# prcm_aon_secure register map
Vendor: Texas Instruments
Peripheral module from a debugger description file (folder CC35X1E).
Registers are 32-bit, access per field, reset 0x0 unless marked. A register's access mark holds for its fields unless they carry their own. Offsets are as the file gives them; lines under a group give offsets from that group; [hi:lo] are bit positions; {n}, {i} and the like mark numbered series; 'fields as' and 'values as' point back to an identical list; <NAME> marks a mode.

## prcm_aon_secure (part 1 of 2)
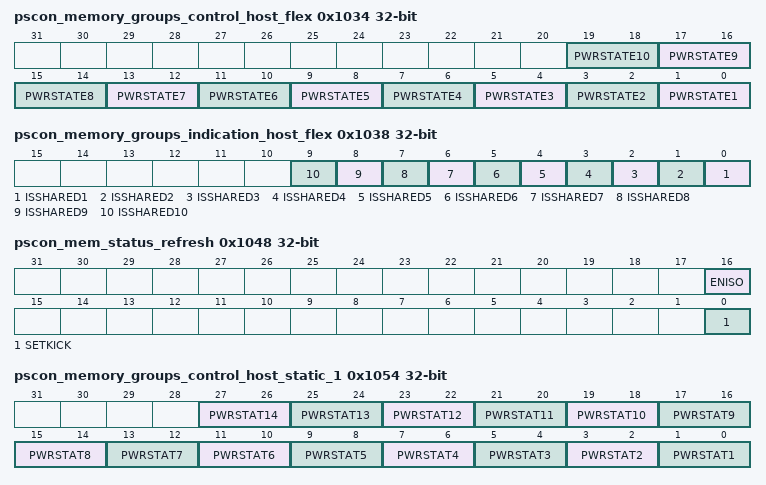
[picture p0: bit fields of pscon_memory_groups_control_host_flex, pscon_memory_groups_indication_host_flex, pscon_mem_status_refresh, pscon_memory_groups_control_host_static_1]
0x1034 pscon_memory_groups_control_host_flex reset not defined — PSCON Memory Groups Control Host Flex. Applicable only if MODE selected flex as HOST memory. Bank power State When owner IP Active/Sleep (power domain is ON/OFF) 0 - OFF/OFF 1 - Reserved 2 - ON/OFF 3 - ON/RET
  [2n-1:2n-2] PWRSTATE{n} rw (n=1..10) — POWER STATE {n} Group {n}
0x1038 pscon_memory_groups_indication_host_flex — PSCON Memory Groups Indication Host Flex Applicable only if MODE selected flex as HOST memory. Memory bank from this group is shared 1 - Shared 0 - Not Shared
  [n-1] ISSHARED{n} rw (n=1..10) — IS SHARED {n} Group {n}
0x1048 pscon_mem_status_refresh reset not defined — PSCON Memory Status Refresh
  [16] ENISO rw — Enable ISO During Refresh '1' - set ISO during refresh '0' - don't set ISO
  [0] SETKICK wo — Memory Host Set Refresh write clear triggers the refresh cycle. first set all memories to desired status, then fire the "refresh" pulse
0x104C pscon_mem_status_refresh_done ro reset 0x3 — Memory Refresh Status
  [0] DONE — memories status refresh is done
0x1054 pscon_memory_groups_control_host_static_1 reset not defined — PSCON Memory Groups Control Host Static. Bank power State When owner IP Active/Sleep (power domain is ON/OFF) 0 - OFF/OFF 1 - Reserved 2 - ON/OFF 3 - ON/RET
  [27:26] PWRSTAT14 rw — POWER STATE 14 Group 36
  [25:24] PWRSTAT13 rw — POWER STATE 13 Group 35
  [23:22] PWRSTAT12 rw — POWER STATE 12 HIF Group 34 - being used as shared memory
  [2n-1:2n-2] PWRSTAT{n} rw (n=1..11) — POWER STATE {n} Group {n+22}
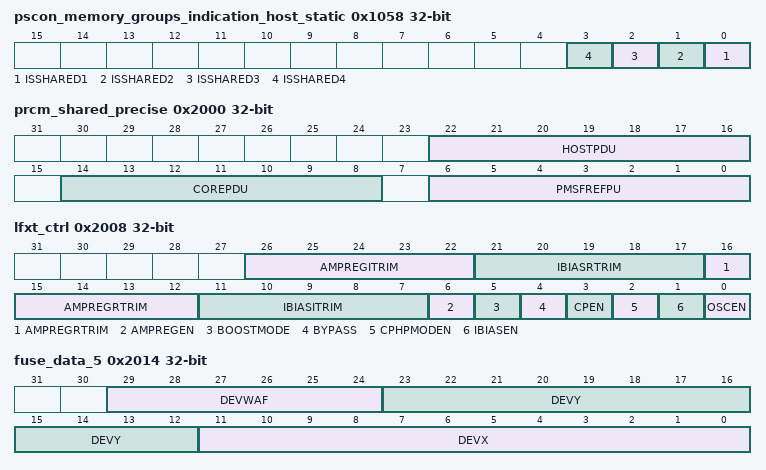
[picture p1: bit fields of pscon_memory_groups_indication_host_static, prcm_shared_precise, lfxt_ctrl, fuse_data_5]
0x1058 pscon_memory_groups_indication_host_static — Memory bank from this group is shared 1 - Shared 0 - Not Shared
  [n-1] ISSHARED{n} rw (n=1..4) — IS SHARED {n} Group {n+22}
0x105C prcm_logic_host_memory_status ro — Logic Host Memory Status
  [13:0] AONIN — Host Memory AONIN indication
0x1060 conectivity_stop reset 0x3 — Connectivity Stop
  [0] SET rw — '1' - Connectivity Stop '0' - Connectivity Start
0x1064 host_rst_ov_ctrl — HOST RESET OV CONTROL reset override control register, active low polarity: '0' - override reset (force reset line to 0, reset asserted, active low) '1' - don't override reset
  [0] PULSE wo — PULSE write clear
0x1068 sleepdeep — The register holds sleepdeep command for the host_mcu for debugging
  [0] SET rw — Set this field to force HOST deepsleep. It will cleared by HW when [HSLPIND] is '1'.
0x2000 prcm_shared_precise — SHARED PRECISE override values for PRCM SHARED Modules
  [22:16] HOSTPDU rw — HOST POWER DOMAIN UP SET precise duration for HOST Power Domain UP - factor 4 slow CLK resolution 0 - 1 Slow CLKs 1 - 5 Slow CLKs 2 - 9 Slow CLKs 3 - 13 Slow CLKs ... 127 - 509 Slow CLKs
  [14:8] COREPDU rw — CORE POWER DOMAIN UP SET precise duration for CORE Power Domain UP - factor 4 slow CLK resolution 0 - 1 Slow CLKs 1 - 5 Slow CLKs 2 - 9 Slow CLKs 3 - 13 Slow CLKs ... 127 - 509 Slow CLKs
  [6:0] PMSFREFPU rw — PMS FREF PLL UP SET precise duration for CORE PRCM Shared UP - factor 4 slow CLK resolution 0 - 1 Slow CLKs 1 - 5 Slow CLKs 2 - 9 Slow CLKs 3 - 13 Slow CLKs ... 127 - 509 Slow CLKs
0x2008 lfxt_ctrl — LFXT CONTROL
  [26:22] AMPREGITRIM rw — AMPLITUDE REGULATION CURRENT TRIM Amplitude regulation current trim
  [21:17] IBIASRTRIM rw — IBIAS RTRIM Constant gm bias resistor ladder trim
  [16:12] AMPREGRTRIM rw — AMPLITUDE REGULATION RESISTOR TRIM Amplitude regulation resistor ladder trim
  [11:7] IBIASITRIM rw — IBIAS ITRIM Constant gm bias current trim
  [6] AMPREGEN rw — AMPLITUDE REGULATION ENABLE Enable amplitude regulation
  [5] BOOSTMODE rw — BOOST MODE Start-up pulse for bias current generation
  [4] BYPASS rw — Bypass LFXT
  [3] CPEN rw — Comparator (slicer) enable
  [2] CPHPMODEN rw — COMP HP MODE EN Comparator high current mode
  [1] IBIASEN rw — Enable constant-gm bias
  [0] OSCEN rw — Oscillator core enable
0x200C lfxt_spare
  [15:0] CTL rw — CTL lfxt spare reg
0x2010 lfosc_en ro — LFOSC ENABLE
  [0] GOOD — CLK GOOD LFOSC clock good indication based on clock qualification logic
0x2014 fuse_data_5 ro
  [29:24] DEVWAF, [23:12] DEVY, [11:0] DEVX
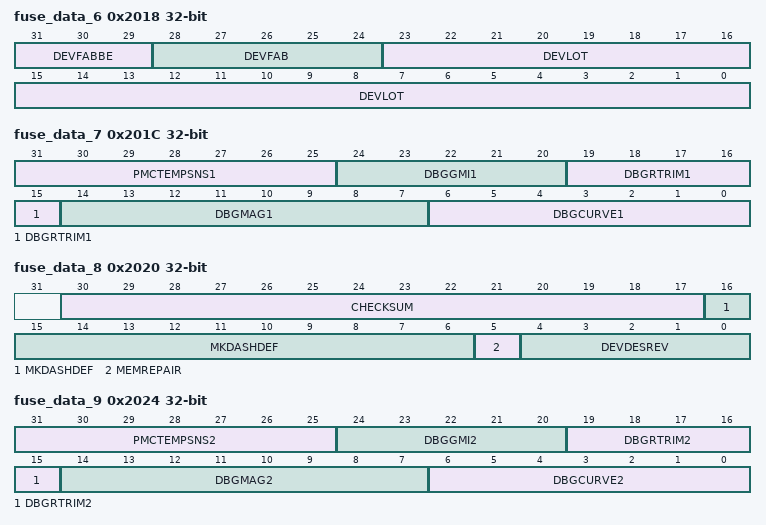
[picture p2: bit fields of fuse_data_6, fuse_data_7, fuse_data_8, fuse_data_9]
0x2018 fuse_data_6 ro
  [31:29] DEVFABBE, [28:24] DEVFAB, [23:0] DEVLOT
0x201C fuse_data_7 ro
  [31:25] PMCTEMPSNS1 — PMCIO TEMP SENSOR 1ST INSERTION For the first insertion.
  [24:20] DBGGMI1 — DIGBG GMI 1ST INSERTION For the first insertion. This field is used for trimming at boot after shift done.
  [19:15] DBGRTRIM1 — DIGBG RTRIM 1ST INSERTION For the first insertion. This field is used for trimming at boot after shift done.
  [14:7] DBGMAG1 — DIGBG MAG 1ST INSERTION For the first insertion. This field is used for trimming at boot after shift done.
  [6:0] DBGCURVE1 — DIGBG CURVE 1St INSERTION For the first insertion. This field is used for trimming at boot after shift done.
0x2020 fuse_data_8 ro
  [30:17] CHECKSUM — Checksum_TI_ DIEID_FUSE_DATA_5_6_8
  [16:6] MKDASHDEF — Make-defined
  [5] MEMREPAIR
  [4:0] DEVDESREV
0x2024 fuse_data_9 ro
  [31:25] PMCTEMPSNS2 — PMCIO TEMP SENSOR 2ND INSERTION For the second insertion. This field is used by SW only.
  [24:20] DBGGMI2 — DIGBG GMI 2ND INSERTION For the second insertion. This field is used by SW only.
  [19:15] DBGRTRIM2 — DIGBG RTRIM 2ND INSERTION For the second insertion. This field is used by SW only.
  [14:7] DBGMAG2 — DIGBG MAG 2ND INSERTION For the second insertion. This field is used by SW only.
  [6:0] DBGCURVE2 — DIGBG CURVE 2ND INSERTION For the second insertion. This field is used by SW only.
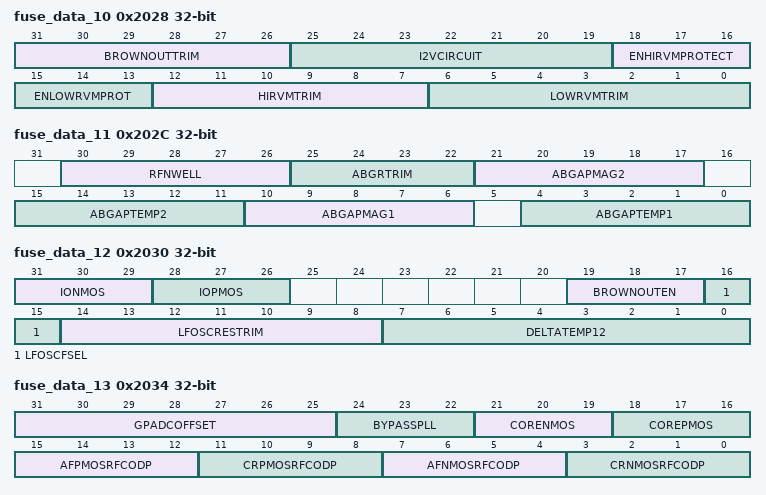
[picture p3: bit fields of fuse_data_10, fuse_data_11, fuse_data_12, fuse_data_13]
0x2028 fuse_data_10 ro
  [31:26] BROWNOUTTRIM — Brownout Trims
  [25:19] I2VCIRCUIT — I2V Circuit (Measure Current using GPADC)
  [18:16] ENHIRVMPROTECT — Enable High RVM protection (Specify whether to use the indication from RVM to reset the device). The RVM Enable can be override by SW (Boot RAM/Privilege mode). 0 - Disable (Ignore indication from RVM) Other (1-7) - Enable (Do not ignore indication from RVM) Consider Splitting the enables (including CRC)
  [15:13] ENLOWRVMPROT — Enable Low RVM protection (Specify whether to use the indication from RVM to reset the device). The RVM Enable can be override by SW (Boot RAM/Privilege mode). 0 - Disable (Ignore indication from RVM) Other (1-7) - Enable (Do not ignore indication from RVM)
  [12:7] HIRVMTRIM — High Digital Supply RVM Trimming
  [6:0] LOWRVMTRIM — Low Digital Supply RVM Trimming
0x202C fuse_data_11 ro
  [30:26] RFNWELL — RF NWELL Will be used to calculate during production the PMREF_V2I_RTRIM - Reference current to the RFCIO RX/TX modules (Can be part of OCP\, Not used in cold boot)
  [25:22] ABGRTRIM — ANA BG RTRIM This field is calculated bases on the 'RF_NWELL_Efuse' trimming results ANABG RTRIM (REFSYS_REG0<9:6>)
  [21:17] ABGAPMAG2 — ANA BGAP MAG 2ND INSERTION For the second insertion. This field is used by SW only.
  [15:11] ABGAPTEMP2 — ANABGAP TEMP 2ND INSERTION Trimming. For the second insertion. This field is used by SW only.
  [10:6] ABGAPMAG1 — ANA BGAP MAG 1St INSERTION For the first insertion. This field is used for trimming at boot after shift done.
  [4:0] ABGAPTEMP1 — ANABGAP TEMP 1ST INSERTION Trimming. For the first insertion. This field is used for trimming at boot after shift done.
0x2030 fuse_data_12 ro
  [31:29] IONMOS
  [28:26] IOPMOS
  [19:17] BROWNOUTEN — Brownout Enable/Disable: 0 - Disable Other (1-7) - Enable (When HW check these bits: if equal to '0' disable otherwise enable)
  [16:15] LFOSCFSEL — LFOSC Frequency Trimming
  [14:8] LFOSCRESTRIM — LFOSC Resistor Trimming
  [7:0] DELTATEMP12 — DELTA TEMP 1ST 2ND INSERTIONS Defines the delta temperature between the 1st and 2nd insertion in degC
0x2034 fuse_data_13 ro
  [31:25] GPADCOFFSET — GPADC OFFSET Capture the offset error of the GPADC
  [24:22] BYPASSPLL — Bypass SoC PLL Other (0-6) - Do not bypass SoC PLL 7 - Bypass SoC PLL
  [21:19] CORENMOS — CORE NMOS SOC ODP
  [18:16] COREPMOS — CORE PMOS SOC ODP
  [15:12] AFPMOSRFCODP — AF PMOS RFCIO ODP
  [11:8] CRPMOSRFCODP — CORE PMOS RFCIO ODP
  [7:4] AFNMOSRFCODP — AF NMOS RFCIO ODP
  [3:0] CRNMOSRFCODP — CORE NMOS RFCIO ODP
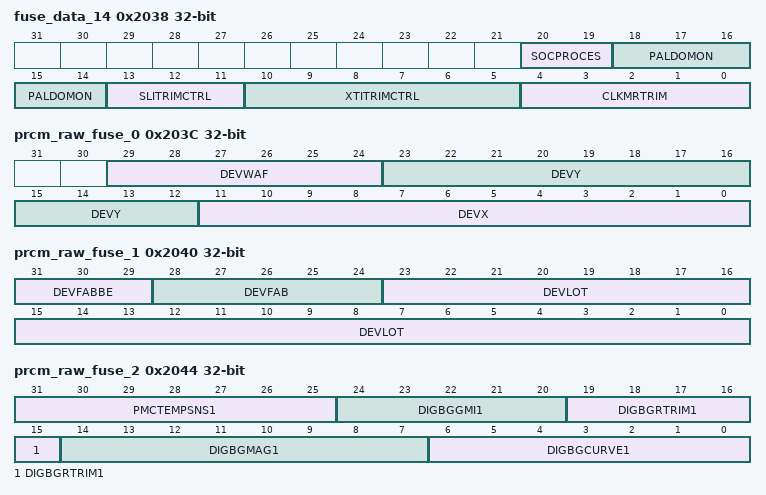
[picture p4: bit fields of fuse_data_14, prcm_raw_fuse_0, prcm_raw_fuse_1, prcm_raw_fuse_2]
0x2038 fuse_data_14 ro
  [20:19] SOCPROCES — SOC PROCESS The value is calculated based on Core PMOS/NMOS (SoC ODP) 2b'00 - Nominal 2b'01 - Weak 2b'10 - Strong
  [18:14] PALDOMON — PA LDO IN MONITOR PA LDO In ('Battery') Sensor Trimming for 3V
  [13:11] SLITRIMCTRL — Slicer ITRIM Control (CKM_SLICER_REG0<7:5>)
  [10:5] XTITRIMCTRL — XTAL ITRIM control (CKM_OSC_REG0<6:1>)
  [4:0] CLKMRTRIM — CLKM RTRIM This field is calculated base on the 'RF_NWELL_Efuse ' trimming results (CKM_SLICER_REG0<4:0>)
0x203C prcm_raw_fuse_0 ro — PRCM RAW FUSE 0 fuse line 5
  [29:24] DEVWAF, [23:12] DEVY, [11:0] DEVX
0x2040 prcm_raw_fuse_1 ro — PRCM RAW FUSE 1 fuse line 6
  [31:29] DEVFABBE, [28:24] DEVFAB, [23:0] DEVLOT
0x2044 prcm_raw_fuse_2 ro — PRCM RAW FUSE 2 fuse line 7
  [31:25] PMCTEMPSNS1 — PMCIO TEMP SENSOR 1ST INSERTION For the first insertion.
  [24:20] DIGBGGMI1 — DIGBG GMI 1ST INSERTION For the first insertion. This field is used for trimming at boot after shift done.
  [19:15] DIGBGRTRIM1 — DIGBG RTRIM 1ST INSERTION For the first insertion. This field is used for trimming at boot after shift done.
  [14:7] DIGBGMAG1 — DIGBG MAG 1ST INSERTION For the first insertion. This field is used for trimming at boot after shift done.
  [6:0] DIGBGCURVE1 — DIGBG CURVE 1ST INSERTION For the first insertion. This field is used for trimming at boot after shift done.
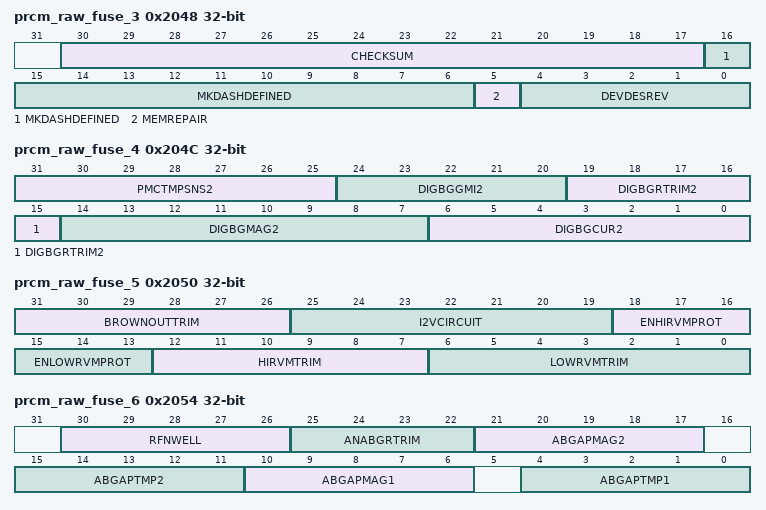
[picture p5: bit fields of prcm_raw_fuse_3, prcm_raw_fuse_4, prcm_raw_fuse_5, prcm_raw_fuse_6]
0x2048 prcm_raw_fuse_3 ro — PRCM RAW FUSE 3 fuse line 8
  [30:17] CHECKSUM — Checksum_TI_ DIEID_FUSE_DATA_5_6_8
  [16:6] MKDASHDEFINED — Make-defined
  [5] MEMREPAIR
  [4:0] DEVDESREV
0x204C prcm_raw_fuse_4 ro — PRCM RAW FUSE 4 fuse line 9
  [31:25] PMCTMPSNS2 — PMCIO TEMP SENSOR 2ND INSERTION For the second insertion. This field is used by SW only.
  [24:20] DIGBGGMI2 — DIGBG GMI 2ND INSERTION For the second insertion. This field is used by SW only.
  [19:15] DIGBGRTRIM2 — DIGBG RTRIM 2ND INSERTION For the second insertion. This field is used by SW only.
  [14:7] DIGBGMAG2 — DIGBG MAG 2ND INSERTION For the second insertion. This field is used by SW only.
  [6:0] DIGBGCUR2 — DIGBG CURVE 2ND INSERTION For the second insertion. This field is used by SW only.
0x2050 prcm_raw_fuse_5 ro — PRCM RAW FUSE 5 fuse line 10
  [31:26] BROWNOUTTRIM — Brownout Trims
  [25:19] I2VCIRCUIT — I2V Circuit (Measure Current using GPADC)
  [18:16] ENHIRVMPROT — Enable High RVM protection (Specify whether to use the indication from RVM to reset the device). The RVM Enable can be override by SW (Boot RAM/Privilege mode). 0 - Disable (Ignore indication from RVM) Other (1-7) - Enable (Do not ignore indication from RVM) Consider Splitting the enables (including CRC)
  [15:13] ENLOWRVMPROT — Enable Low RVM protection (Specify whether to use the indication from RVM to reset the device). The RVM Enable can be override by SW (Boot RAM/Privilege mode). 0 - Disable (Ignore indication from RVM) Other (1-7) - Enable (Do not ignore indication from RVM)
  [12:7] HIRVMTRIM — High Digital Supply RVM Trimming
  [6:0] LOWRVMTRIM — Low Digital Supply RVM Trimming
0x2054 prcm_raw_fuse_6 ro — PRCM RAW FUSE 6 fuse line 11
  [30:26] RFNWELL — RF NWELL EFUSE Will be used to calculate during production the PMREF_V2I_RTRIM - Reference current to the RFCIO RX/TX modules (Can be part of OCP\, Not used in cold boot)
  [25:22] ANABGRTRIM — ANA BG RTRIM This field is calculated bases on the 'RF_NWELL_Efuse' trimming results ANABG RTRIM (REFSYS_REG0<9:6>)
  [21:17] ABGAPMAG2 — ANA BGAP MAG 2ND INSERTION For the second insertion. This field is used by SW only.
  [15:11] ABGAPTMP2 — ANABGAP TEMP 2ND INSERTION Trimming. For the second insertion. This field is used by SW only.
  [10:6] ABGAPMAG1 — ANA BGAP MAG 1ST INSERTION For the first insertion. This field is used for trimming at boot after shift done.
  [4:0] ABGAPTMP1 — ANABGAP TEMP 1ST INSERTION Trimming. For the first insertion. This field is used for trimming at boot after shift done.
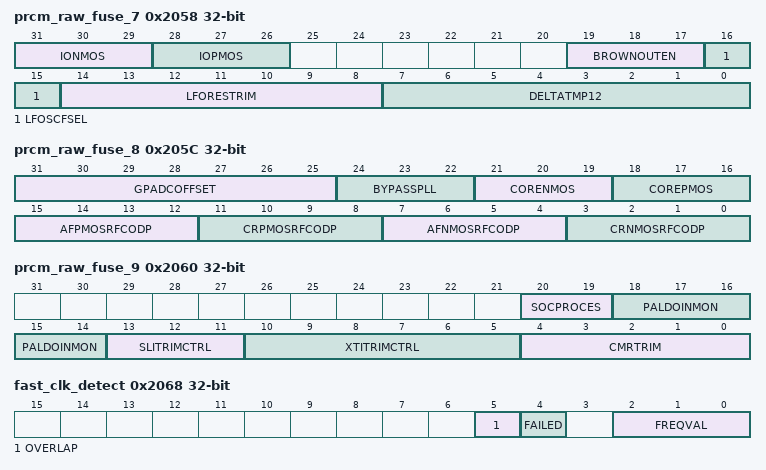
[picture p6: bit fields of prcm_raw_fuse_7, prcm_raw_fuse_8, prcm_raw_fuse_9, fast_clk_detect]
0x2058 prcm_raw_fuse_7 ro — PRCM RAW FUSE 7 fuse line 12
  [31:29] IONMOS
  [28:26] IOPMOS
  [19:17] BROWNOUTEN — Brownout Enable/Disable: 0 - Disable Other (1-7) - Enable (When HW check these bits: if equal to '0' disable otherwise enable)
  [16:15] LFOSCFSEL — LFOSC Frequency Trimming
  [14:8] LFORESTRIM — LFOSC Resistor Trimming
  [7:0] DELTATMP12 — DELTA TEMPERATURE 1ST 2ND INSERTIONS Defines the delta temperature between the 1st and 2nd insertion in degC
0x205C prcm_raw_fuse_8 ro — PRCM RAW FUSE 8 fuse line 13
  fields as fuse_data_13
0x2060 prcm_raw_fuse_9 ro — PRCM RAW FUSE 9 fuse line 14
  [20:19] SOCPROCES — SOC PROCESS The value is calculated based on Core PMOS/NMOS (SoC ODP) 2b'00 - Nominal 2b'01 - Weak 2b'10 - Strong
  [18:14] PALDOINMON — PA LDO IN MONITOR PA LDO In ('Battery') Sensor Trimming for 3V
  [13:11] SLITRIMCTRL — Slicer ITRIM Control (CKM_SLICER_REG0<7:5>)
  [10:5] XTITRIMCTRL — XTAL ITRIM control (CKM_OSC_REG0<6:1>)
  [4:0] CMRTRIM — CLKM RTRIM This field is calculated base on the 'RF_NWELL_Efuse ' trimming results (CKM_SLICER_REG0<4:0>)
0x2064 prcm_raw_fuse_10 ro — PRCM RAW FUSE 10 fuse line 15
0x2068 fast_clk_detect ro — FAST CLK DETECTION primary clock detection result
  [5] OVERLAP — Not in use. '1' - if FREF value is overlapping at 40/48MHz or 48/52MHz
  [4] FAILED — fast clock detection FSM failed counter was no in any FREQ boundaries '1' - failed '0' - OK
  [2:0] FREQVAL — FAST CLK FREQUENCY DETECTION VALUE fast clock detection value : 0: 10MHz 1: 26MHz 2: 40MHz 3: 52MHz
0x206C soc_pll_lock_loss_config
  [0] CLR wo — CLEAR write clear Clear Lock Loss Status.
0x2070 soc_pll_lock_loss_status ro
  [0] STA — STATUS Lock Loss Status. Set when SOC PLL is low during active (PD Core ON). This indication is latch asynchronously since lock low implies no SOC PLL clock is available. In PLL Bypass mode (e.g. SOP = DoA) this indication is ignored. (Yet, in SOP = DoA , when SOP bypass is applied, and SOC PLL is no more bypassed, this indication is valid)
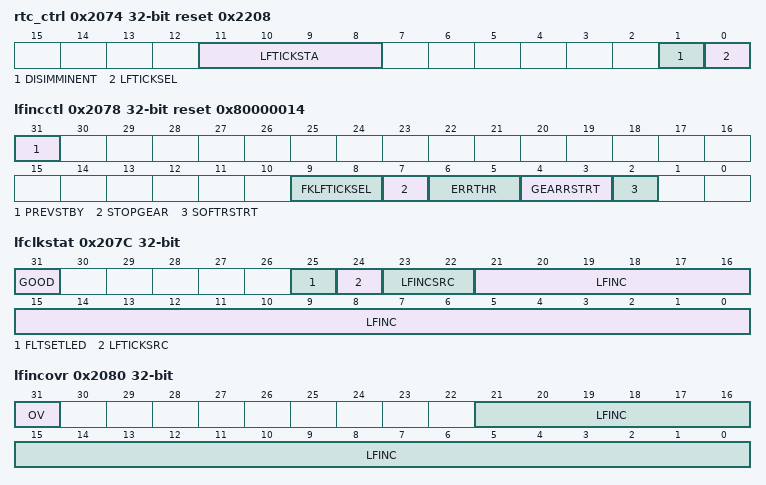
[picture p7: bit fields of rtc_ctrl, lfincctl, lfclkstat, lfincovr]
0x2074 rtc_ctrl reset 0x2208 (reset mask 0xFFFFFFFC) — RTC CONTROL
  [11:8] LFTICKSTA ro — LFTICK STATE '1101' - Real LFTICK '1100' - Gate RTC CLK '1110' - Force LFTICK high '1010' - Switch RTC CLK low '0010' - Standby '0000' - Force LFTICK low '0100' - switch RTC CLK high '0101' - Ungate RTC CLK
  [1] DISIMMINENT rw — NOT USED - DO NOT CHANGE VALUE '1' - disables imminent option towards SYSTIMER '0' - enables imminent
  [0] LFTICKSEL rw — LFTICK SELECT '1' - use real LFTICK '0' - use fake LFTICK
0x2078 lfincctl reset 0x80000014 — LFINC CONTROL Low frequency time increment control
  [31] PREVSTBY rw — PREVENT STANDBY Controls if the LFINC filter prevents STANDBY entry until settled.
    0=OFF (Disable. Do not prevent STANDBY entry.); 1=ON (Enable. Prevent STANDBY entry.)
  [9:8] FKLFTICKSEL rw — FAKE LFTICK SELECTOR '00' - default - LOKI + corner case scenario '01' - first integration '10' - LOKI '11' - always enable
    2=MIDSMALL (Middle value towards SMALL.); 1=MIDLARGE (Middle value towards LARGE.); 0=LARGE (Restart gearing on large error. Fewer false restarts, slower response on small frequency shifts.); 3=SMALL (Restart gearing on small error. Potentially more false restarts, faster response on small frequency shifts.)
  [7] STOPGEAR rw — STOP GEAR Controls the final gear of the LFINC filter.
    0=LOW (Lowest final gear. Best settling, but less dynamic frequency tracking.); 1=HIGH (Highest final gear. Best dynamic frequency tracking, but higher variation in filter value.)
  [6:5] ERRTHR rw — ERROR THRESHOLD Controls the threshold for gearing restart of the LFINC filter. Only effective if [GEARRSTRT] is not ONETHR or TWOTHR.
    values as FKLFTICKSEL
  [4:3] GEARRSTRT rw — GEAR RESTART Controls gearing restart of the LFINC filter.
    2=TWOTHR (Restart gearing when the error accumulator crosses the threshold twice in a row.); 1=ONETHR (Restart gearing when the error accumulator crosses the threshold once.); 0=NEVER (Never restart gearing. Very stable filter value, but very slow response on frequency changes.)
  [2] SOFTRSTRT rw — SOFT RESTART Use a higher gear after re-enabling / wake-up. The filter will require 16-24 LFCLK periods to settle (depending on [STOPGEAR]), but may respond faster to frequency changes during STANDBY.
    1=ON (Use soft gearing restarts); 0=OFF (Don't use soft gearing restarts)
0x207C lfclkstat ro — LFCLK STATUS Low-frequency clock status
  [31] GOOD — Low frequency clock good Note: This is only a coarse frequency check based on [LFQUALCTL.*]. The clock may not be accurate enough for timing purposes.
  [25] FLTSETLED — FILTER SETTLED LFINC filter is running and settled.
  [24] LFTICKSRC — Source of LFTICK.
    0=LFCLK (LFTICK generated from the selected LFCLK); 1=FAKE (LFTICK generated from CLKULL (LFCLK not available))
  [23:22] LFINCSRC — Source of LFINC used by the RTC. This value depends on [LFINCOVR.OVERRIDE], LF clock availability, HF tracking loop status and the device state (ACTIVE/STANDBY).
    2=OVERRIDE (Using override value from [LFINCOVR.LFINC]); 0=MEAS (Using measured value. This value is updated by hardware and can be read from [LFINC].); 1=AVG (Using filtered / average value. This value is updated by hardware and can be read and updated in [LFINCCTL.INT].); 3=FAKE (Using FAKE LFTICKs with corresponding LFINC value.)
  [21:0] LFINC — Measured value of LFCLKSTAT_LFINC. Given in microseconds with 16 fractional bits. This value is calculated by Hardware. It is the LFCLK period according to CLKULL cycles.
0x2080 lfincovr — LFINC OVERRIDE Low frequency time increment override control
  [31] OV rw — Override LF increment Use the value provided in [LFINC] instead of the value calculated by Hardware.
  [21:0] LFINC rw — LF increment value This value is used when [OVERRIDE] is set to 1. Otherwise the value is calculated automatically.
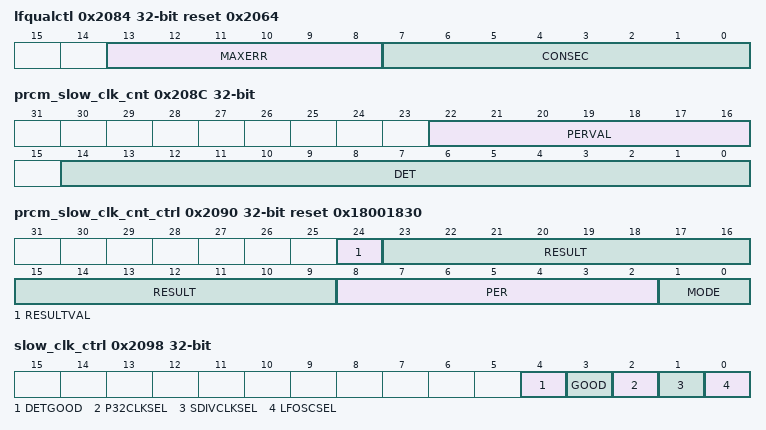
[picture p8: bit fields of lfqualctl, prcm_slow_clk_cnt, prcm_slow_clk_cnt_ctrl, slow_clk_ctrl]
0x2084 lfqualctl reset 0x2064 — Low frequency clock qualification control
  [13:8] MAXERR rw — Maximum LFCLK period error. Value given in microseconds, 3 integer bits + 3 fractional bits.
  [7:0] CONSEC rw — Number of consecutive times the LFCLK period error has to be smaller than [MAXERR] to be considered "good". Setting this value to 0 will bypass clock qualification, and the "good" indicator will always be 1.
0x2088 lfincctl_int reset 0x1E8480 — Low frequency time increment value
  [21:0] INT rw — Increment override value write opt SW and HW can write this value Integral part of the LFINC filter. This value is updated by Hardware to reflect the current state of the filter. It can also be written to change the current state.
0x208C prcm_slow_clk_cnt ro — SLOW CLK COUNT
  [22:16] PERVAL — PERIOD VALUE slow CLK current value. bounds are 0 to slow_clk_counter_period
  [14:0] DET — FAST CLK DETECTION COUNTER VALUE Counter results for 4 slow clock freq lower upper (MHz) (dec) (dec) 10 1190 1503 26 3094 3908 40 4760 6012 52 6188 7815
0x2090 prcm_slow_clk_cnt_ctrl reset 0x18001830 (reset mask 0xFEFFFFFC) — SLOW CLOCK COUNTER CONTROL
  [24] RESULTVAL ro — RESULT VALID read clear pulse Determine whether the measurement is in progress or done: 0x0 - In progress (Relevant in one shot only) 0x1 - Done (when finish measurement and result ready)
  [23:9] RESULT ro — RESULT Slow Clock counter result
  [8:2] PER rw — PERIOD Determine the Slow clock counter period (Slow Clock cycles), 1 - 128. '0' - 1 CLK cycle '1' - 2 CLK cycles '2' - 3 CLK cycles ... '127' - 128 CLK cycles
  [1:0] MODE rw — MODE Determine the Slow clock counter mode- 0x3 - Reserved 0x2 - Periodic 0x1 - One Shot 0x0 - Disable
0x2094 prcm_slow_clk_cnt_start — SLOW CLK COUNT START KICK
  [0] EN wo — ENABLE write clear start the FREQUENCY DETECTION. MEM_SLOW_CLK_COUNTER_MODE should be set prior to the start indication
0x2098 slow_clk_ctrl — SLOW CLK CONTROL
  [4] DETGOOD ro — DETECTION GOOD '1' - means 5 edges detected of LFXT/EXT/XTAL
  [3] GOOD rw — '1' - set LFXT CLK good
  [2] P32CLKSEL rw — PLL CLOCK SELECTOR '0' - LFCLK (real tick should be selected) '1' - PLL32 CLK (fake tick should be selected)
  [1] SDIVCLKSEL rw — SLOW CLOCK DIVISION SELECTOR 1 - select LFXT/EXT/XTAL CLK DIV 8 0 - select LFXT/EXT/XTAL CLK
  [0] LFOSCSEL rw — LFOSC SELECTOR 0 - select RCOSC 1 - select LFXT/EXT/XTAL
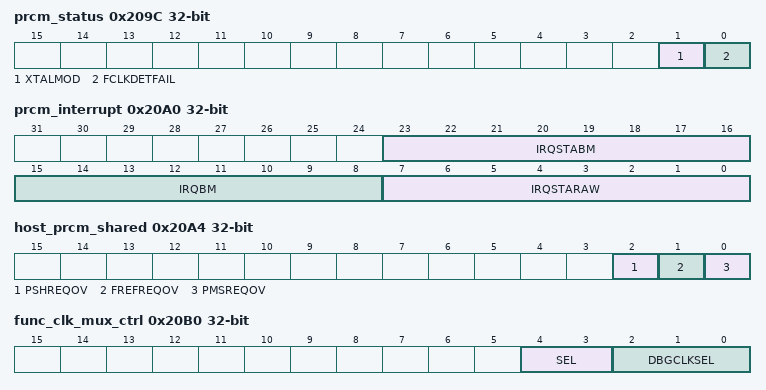
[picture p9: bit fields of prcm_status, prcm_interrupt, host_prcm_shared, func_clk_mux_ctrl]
0x209C prcm_status ro
  [1] XTALMOD — XTAL MODE '1' - XTAL mode '0' - TCXO External mode
  [0] FCLKDETFAIL — FAST CLK DETECTIOn FAILED '1' - FREF detection failed
0x20A0 prcm_interrupt — [0]- indication at slow CLK calibration for one shot mode. [1] - lfinc_updated [2] - lfinc_gearing_restart [3] - lfclk_oor [4] - lfclk_loss [5] - NU [6] - NU [7] - NU
  [23:16] IRQSTABM ro — IRQs indication after Mask
  [15:8] IRQBM rw — PRCM IRQ mask option
  [7:0] IRQSTARAW ro — PRCM IRQ Clear indication and raw status read clear
0x20A4 host_prcm_shared — HOST PRCM SHARED override values for PRCM SHARED Modules
  [2] PSHREQOV rw — PLL REQUEST OVERRIDE '1' - keeps awake at sleep state '0' - regular operation note: in order to set this field as '1', FREF OV and PMS OV must be set as well.
  [1] FREFREQOV rw — FREF REQUEST OVERRIDE '1' - keeps awake at sleep state '0' - regular operation note: in order to set this field as '1', PMS OV must be set as well.
  [0] PMSREQOV rw — PMS REQUEST OVERRIDE '1' - keeps awake at sleep state '0' - regular operation
0x20A8 core_sleep_indication ro
  [0] CTLSTAT — CONTROL STATE '1' - CORE is SLEEP '0' - CORE is in ACTIVE or gets into ACTIVE
0x20AC host_sleep_indication ro
  [0] CTLSTAT — CONTROL STATE '1' - HOST is SLEEP '0' - HOST is in ACTIVE or gets into ACTIVE
0x20B0 func_clk_mux_ctrl — PRCM functional selection towards FAST CLK DETECTION '00000' - prcm_fast_clock 'xxx01' - ospr_hsm_tst_fro_clk_out 'xxx10' - clk_gpadc_clk 'xxx11' - fref_2m_socpll_1p8v 'xx100' - rf_pll_divided_clk '01000' - src_clk_40 '10000' - lfxt / xtal / ext '11000' - rcosc
  [4:3] SEL rw — Fast CLK detection selector MEM_DBG_CLK_SEL should be set 3'b0 for this reg to take place '00' - prcm_fast_clock. '01' - src_clk_40 '10' - lfxt / xtal / ext '11' - rcosc
  [2:0] DBGCLKSEL ro — Debug and Fast CLK detection selector 'x00' - prcm_fast_clock. 'x01' - ospr_hsm_tst_fro_clk_out 'x10' - clk_gpadc_clk 'x11' - fref_2m_socpll_1p8v '100' - rf_pll_divided_clk
0x20B4 rst_ctrl — RESET CONTROL
  [0] SOCAON wo — SOC AON write clear '1' - set reset
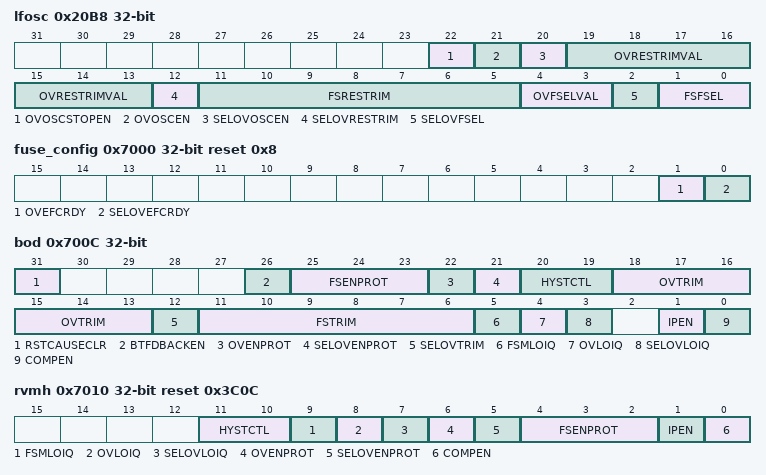
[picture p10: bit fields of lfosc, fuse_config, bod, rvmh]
0x20B8 lfosc — LFOSC OVERRIDE STATUS
  [22] OVOSCSTOPEN rw — OVERRIDE OSC STOP EN LFOSC STOP enable override value
  [21] OVOSCEN rw — OVERRIDE OSC EN LFOSC enable override value
  [20] SELOVOSCEN rw — SELECTOR OVERRIDE OSC ENABLE LFOSC enable override select
  [19:13] OVRESTRIMVAL rw — OVERRIDE RESISTOR SELECTOR VALUE LFOSC RES trim override value
  [12] SELOVRESTRIM rw — SELECTOR OVERRIDE RESISTOR TRIM LFOSC RES trim override select
  [11:5] FSRESTRIM ro — FUSE RESISTOR TRIM Analog band gap rtrimfuse value for LFOSC rtrim
  [4:3] OVFSELVAL rw — OVERRIDE FSEL SELECTOR VALUE LFOSC frequency trim override value
  [2] SELOVFSEL rw — SELECT OVERRIDE FSEL LFOSC frequency trim override select
  [1:0] FSFSEL ro — LFOSC frequency trim value
0x7000 fuse_config reset 0x8 (reset mask 0xFFFFFFFC) — FUSE CONFIG config efc ready
  [1] OVEFCRDY rw — OVERRIDE EFC READY VALUE
  [0] SELOVEFCRDY rw — SELECT OVERRIDE EFC READY '1' selects ov_efc_ready reg
0x7004 pmcio ro
  [1:0] SOPSTA — SOP status output from POL sequencer
0x700C bod reset not defined — BODCTL
  [31] RSTCAUSECLR rw — BOD reset cause clear value Set '1' to this field will automated a pulse to pmu. clear this field to '0' after use.
  [26] BTFDBACKEN ro — boot feedback for bod enable status
  [25:23] FSENPROT ro — bod protection enable fuse value
  [22] OVENPROT rw — override value for BOD protection enable
  [21] SELOVENPROT rw — select BOD protection enable '1' - select override '0' - select fuse
  [20:19] HYSTCTL rw — BOD hysteresis control
  [18:13] OVTRIM rw — BOD trim override value
  [12] SELOVTRIM rw — BOD trim override select
  [11:6] FSTRIM ro — BOD fuse trim value
  [5] FSMLOIQ ro — FSM bod low IQ status
  [4] OVLOIQ rw — OVERRIDE LOW IQ BOD Comparator low IQ power mode override value
  [3] SELOVLOIQ rw — SELECTOR OVERRIDE BOD LOW IQ BOD Comparator low IQ power mode override select
  [1] IPEN rw — IP ENABLE BOD Comparator input Enable value
  [0] COMPEN rw — BOD COMPARATOR ENABLE Enable value
0x7010 rvmh reset 0x3C0C (reset mask 0xFFFFFC1C) — RVM HIGH CONTROL
  [11:10] HYSTCTL rw — RVMH hysteresis control
  [9] FSMLOIQ ro — FSM rvml lo IQ status
  [8] OVLOIQ rw — RVMH Comparator low IQ power mode override value
  [7] SELOVLOIQ rw — RVMH Comparator low IQ power mode override select
  [6] OVENPROT rw — RVMH Comparator En protection mode override value (Override the fuse value) 1 - RVM Hi violation will NOT be detected by device (PMU.POL) 1 - RVM Hi violation will be detected by device (PMU.POL)
  [5] SELOVENPROT rw — RVMH Comparator En protection power mode override select (override fuse value)
  [4:2] FSENPROT ro — RVMH Comparator En protection fuse data
  [1] IPEN rw — RVMH Comparator input Enable
  [0] COMPEN rw — RVMH COMPARATOR Enable
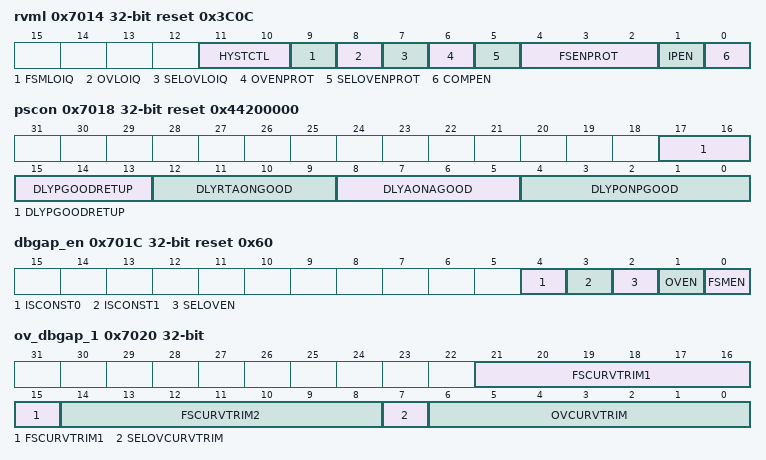
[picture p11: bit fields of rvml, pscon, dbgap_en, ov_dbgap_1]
0x7014 rvml reset 0x3C0C (reset mask 0xFFFFFC1C) — RVM LOW CONTROL
  [11:10] HYSTCTL rw — RVMH hysteresis control
  [9] FSMLOIQ ro — FSM rvml lo IQ status
  [8] OVLOIQ rw — RVML Comparator low IQ power mode override value
  [7] SELOVLOIQ rw — RVML Comparator low IQ power mode override select
  [6] OVENPROT rw — RVML Comparator En protection mode override value (Override the fuse value) 1 - RVM Low violation will NOT be detected by device (PMU.POL) 1 - RVM Low violation will be detected by device (PMU.POL)
  [5] SELOVENPROT rw — RVML Comparator En protection power mode override select (override fuse value)
  [4:2] FSENPROT ro — RVML Comparator En protection fuse data
  [1] IPEN rw — RVML Comparator input Enable override value
  [0] COMPEN rw — RVML Enable override value
0x7018 pscon reset 0x44200000 (reset mask 0xFFFC0000) — PSCON MEMORY DELAY CONTROL
  [17:13] DLYPGOODRETUP rw — DELAY BETWEEN PGOOD to RET UP 0000:0.8us; 0001:1.6us; 0010:2.4us; 0011:3.2us;...;1001:8us;1111:12.8us
  [12:9] DLYRTAONGOOD rw — DELAY BETWEEn RTAOn to RTAGOOD 0000:0.8us; 0001:1.6us; 0010:3us; 0011:3.2us;...;1001:8us;1111:12.8us
  [8:5] DLYAONAGOOD rw — DELAY BETWEEN AON to AGOOD 0000:0.8us; 0001:1.6us; 0010:2.4us; 0011:3.2us;...;1001:8us;1111:12.8us
  [4:0] DLYPONPGOOD rw — DELAY BETWEEN PON to PGOOD 0000:0.8us; 0001:1.6us; 0010:2.4us; 0011:3.2us;...;1001:8us;1111:12.8us
0x701C dbgap_en reset 0x60 (reset mask 0xFFFFFFE0) — digital bandgap enable register
  [4] ISCONST0 rw — IS CONSTANT 0 1: keep the DBGAP off during sleep BG disable and SW disable 0: allow hibernate
  [3] ISCONST1 rw — IS CONSTANT 1 1: keep the DBGAP on during sleep BG enable and SW enable 0: allow hibernate
  [2] SELOVEN rw — SELECT OVERRIDE ENABLE 1: select override value for DBGAP enable : 0: DBGAP enable according to FSM
  [1] OVEN rw — override value for DBGAP enable
  [0] FSMEN ro — FSM DIGBG enable status
0x7020 ov_dbgap_1 — DBGAP override register
  [21:15] FSCURVTRIM1 ro — FS 1st insertion curve
  [14:8] FSCURVTRIM2 ro — FS 2nd insertion curve
  [7] SELOVCURVTRIM rw — SELECT OVERRIDE CURVE VTRIM 1: select override for curve trim : 0: select curve trim from fuse
  [6:0] OVCURVTRIM rw — override value for DBGAP curve trim : used until fuse chain or when selected
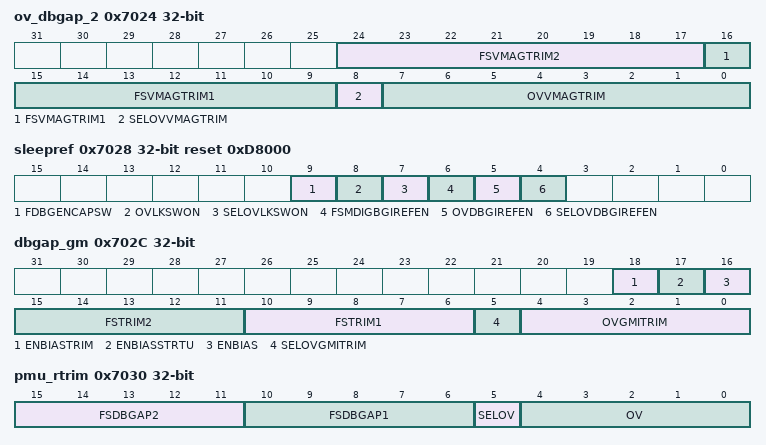
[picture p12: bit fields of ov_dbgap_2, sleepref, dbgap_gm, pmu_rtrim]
0x7024 ov_dbgap_2 — DBGAP override register
  [24:17] FSVMAGTRIM2 ro — fuse value for magnitude 2nd insertion trim
  [16:9] FSVMAGTRIM1 ro — fuse value for magnitude 1st insertion trim
  [8] SELOVVMAGTRIM rw — SELECT OVERRIDE MAG TRIM 1: select override for mag trim : 0: select mag trim from fuse
  [7:0] OVVMAGTRIM rw — override value for DBGAP mag trim : used until fuse chain or when selected
0x7028 sleepref reset 0xD8000 (reset mask 0xFFFFFC00) — SLEEP REFERENCE
  [9] FDBGENCAPSW ro — FSM digital bad gap enable cap status
  [8] OVLKSWON rw — override value for DBGAP switch en
  [7] SELOVLKSWON rw — SELECT OVERRIDE LEAKAGE SWITCH ON 1: select override value for the DBGAP switch on : 0: prcm_leakage_sw_on controlled by FSM
  [6] FSMDIGBGIREFEN ro — FSM digital band gap iref enable status
  [5] OVDBGIREFEN rw — OVERRIDE DBGAP IREF EN
  [4] SELOVDBGIREFEN rw — SELECT OVERRIDE DBGAP IREF ENABLE
0x702C dbgap_gm reset not defined — Digital Band Gap GM GMBIAS config register
  [18] ENBIASTRIM rw — ENABLE BIAS TRIM Enable Trim to GMBIAS module
  [17] ENBIASSTRTU rw — ENABLE BOAS STARTUP Startup control from PRCM to power-up GMBIAS.
  [16] ENBIAS rw — dedicated enable for GMBIAS module
  [15:11] FSTRIM2 ro — fuse value for gmi 2nd insertion trim
  [10:6] FSTRIM1 ro — fuse value for gmi 1st insertion trim Trim for GMBIAS IREF current
  [5] SELOVGMITRIM rw — SELECT OVERRIDE GMI TRIM 1: select override value for dbgap_gmi_trim : 0: fuse value
  [4:0] OVGMITRIM rw — override value for dbgap_gmi_trim
0x7030 pmu_rtrim
  [15:11] FSDBGAP2 ro — fuse value for resistor trim 2st insertion
  [10:6] FSDBGAP1 ro — fuse value for resistor trim 1st insertion
  [5] SELOV rw — SELECT OVERRIDE
  [4:0] OV rw — OVERRIDE value for PMU RTRIM
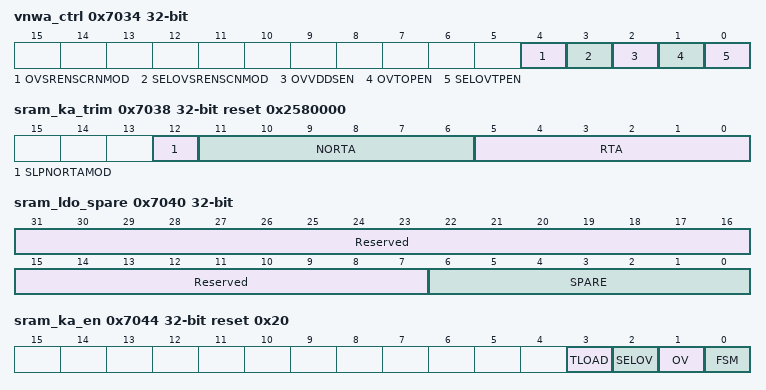
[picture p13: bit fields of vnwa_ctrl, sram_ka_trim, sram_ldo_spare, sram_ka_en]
0x7034 vnwa_ctrl — VNWA CONTROL
  [4] OVSRENSCRNMOD rw — OVERRIDE SRAM ENABLE SCREEN MODE
  [3] SELOVSRENSCNMOD rw — SELECT OVERRIDE SRAM ENABLE SCREEN MODE
  [2] OVVDDSEN rw — OVERRIDE VDD ENABLE
  [1] OVTOPEN rw — OVERRIDE TOP ENABLE
  [0] SELOVTPEN rw — SELECT OVERRIDE TOP ENABLE
0x7038 sram_ka_trim reset 0x2580000 (reset mask 0xFFFFE000)
  [12] SLPNORTAMOD rw — SLEEP NO RTA MODE when '1' chooses the no rta mode trim value
  [11:6] NORTA rw — SRAM KA trim value in NON RTA mode 0.6v : FSM can move memories to NON RTA mode when feature is enabled and WLAN in OFF : When WLAN is ON the BRG HP memories don't support such low array value
  [5:0] RTA rw — SRAM KA trim value in RTA mode - default mode
0x7040 sram_ldo_spare — VALUE
  [31:7] Reserved ro — bit [7]- prcm_sramldo_en_inrush_limit_lowv
  [6:0] SPARE rw — SPARE REG for SRAM LDO
0x7044 sram_ka_en reset 0x20 (reset mask 0xFFFFFFF0) — SRAM KA ENABLE
  [3] TLOAD rw — Enable test load for SRAM keep alive
  [2] SELOV rw — SELECT OVERRIDE 1: select override value for SRAM KA enable : 0: SRAM KA enable from FSM
  [1] OV rw — override value for SRAM KA
  [0] FSM ro — status of final SRAM KA enable
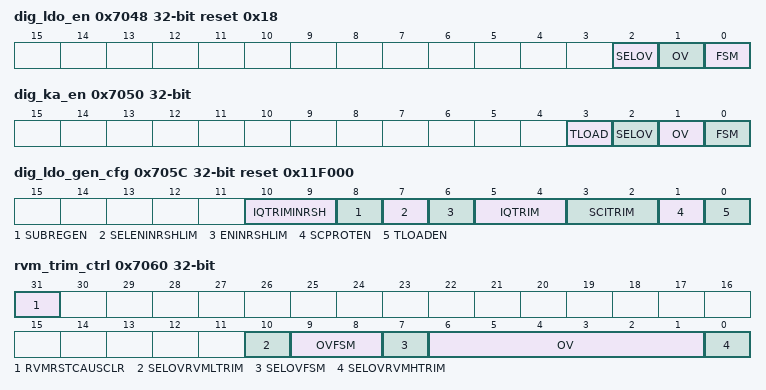
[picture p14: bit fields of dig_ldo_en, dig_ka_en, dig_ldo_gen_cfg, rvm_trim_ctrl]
0x7048 dig_ldo_en reset 0x18 (reset mask 0xFFFFFFF8) — DIG LDO ENABLE
  [2] SELOV rw — 1: select override value for DIG LDO enable : 0: DIG LDO enable from FSM
  [1] OV rw — override value for DIG LDO
  [0] FSM ro — status of FSM DIG LDO enable
0x704C dig_ldo_trim_ov reset 0x1C7 — override register for DIG LDO TRIM
  [5:0] OPP1 rw — digital ldo vtrim value 1.1V
0x7050 dig_ka_en — DIG KA ENABLE
  [3] TLOAD rw — Enable test load for DIG keep alive
  [2] SELOV rw — 1: select override value for DIG KA enable : 0: DIG KA enable from FSM
  [1] OV rw — override value for DIG KA
  [0] FSM ro — status of FSM DIG KA enable
0x7054 dig_ka_trim reset 0x659
  [5:0] VAL rw — DIGITAL KEEP ALIVE VTRIM VALUE
0x7058 dig_ldo_lpmode — DIGITAL LDO LOW POWER MODE Enable Low Power Mode for DIGLDO register
  [0] EN rw — set DIG LDO LDO mode
0x705C dig_ldo_gen_cfg reset 0x11F000 (reset mask 0xFFFFF800) — DIGITAL LDO CONFIG
  [10:9] IQTRIMINRSH rw — IQ TRIM INRUSH Value of IQ TRIM selected Dynamically by H/W on exit sleep. Default = 0x1
  [8] SUBREGEN rw — SUB REGULATION ENABLE Sub Regulation switch from RBYR TO LDO
  [7] SELENINRSHLIM rw — Select for S/W Enabling the Inrush Current Limit Mask
  [6] ENINRSHLIM rw — Enable Inrush Current Limit Mask
  [5:4] IQTRIM rw — Quiescent current trim bits for DIG LDO
  [3:2] SCITRIM rw — Short circuit current trim bits for DIG LDO
  [1] SCPROTEN rw — SHORT CIRCUIT PROTECT ENABLE Enable short circuit protection for DIG LDO
  [0] TLOADEN rw — TEST LOAD ENABLE Enable test load for DIG LDO
0x7060 rvm_trim_ctrl — RVM TRIM CONTROL
  [31] RVMRSTCAUSCLR rw — RVM RESET CAUSE CLEAR Set '1' to this field will automated a pulse to pmu. clear this field to '0' after use.
  [10] SELOVRVMLTRIM rw — SELECT OVERRIDE RVML TRIM '1' uses ov input '0' uses fs input
  [9:8] OVFSM rw — OVERRIDE FSM defines override value for rvml fsm
  [7] SELOVFSM rw — SELECT OVERRIDE FSM '1' uses ov input '0' uses fsm input
  [6:1] OV rw — defines override value for rvmh fuse
  [0] SELOVRVMHTRIM rw — SELECT OVERRIDE RVMH TRIM '1' uses ov input '0' uses fs input
0x7064 rvm_trim_pmu_status ro
  [27:26] FSMRVML — status of FSM RVML TRIM value
  [25:19] FSRVML — RVML fuse trim value
  [18:12] RVML — RVML trim status value to pmu
  [11:6] FSRVMH — RVMH fuse trim value
  [5:0] RVMH — RVMH trim status value to pmu
0x7068 rvml_trim_opp_sleep_ctrl — RVML TRIM CONTROL
  [13:7] OVSLP rw — OVERRIDE SLEEP defines trim sleep value
  [6:0] OVOPP1 rw — OVERRIDE OPP1 defines trim opp1 value
0x706C i2v_circuit_ctrl reset 0x1000000 (reset mask 0xFFFF8000) — I2V CIRCUIT CONTROL
  [14:8] OV rw — I2V circuit trim override value
  [7] SELOV rw — SELECT OVERRIDE I2V circuit trim override select
  [6:0] FS ro — fuse value of I2V circuit
0x7070 pmbist_ctrl — PMBIST CONTROL
  [7] VTDETCMPBMEN rw — VT DETECTOR COMPARATOR BIT MASK ENABLE '1' - enable propagation of VTDET Comparator output '0' - disable Comparator
  [6] PORCMPBMEN rw — POR COMP BIT MASK ENABLE '1' - enable propagation of POR Comparator output '0' - disable Comparator
  [5] EN rw — '1' - enable PMBIST module
  [4] BM rw — BIT MASK '1' - mask bit 0
  [3:0] VAL rw — one hot bit decoder 4 to 16
0x7074 pmu_comp ro — PMU COMPARATOR
  [2] RVMH, [1] RVML, [0] BOD
